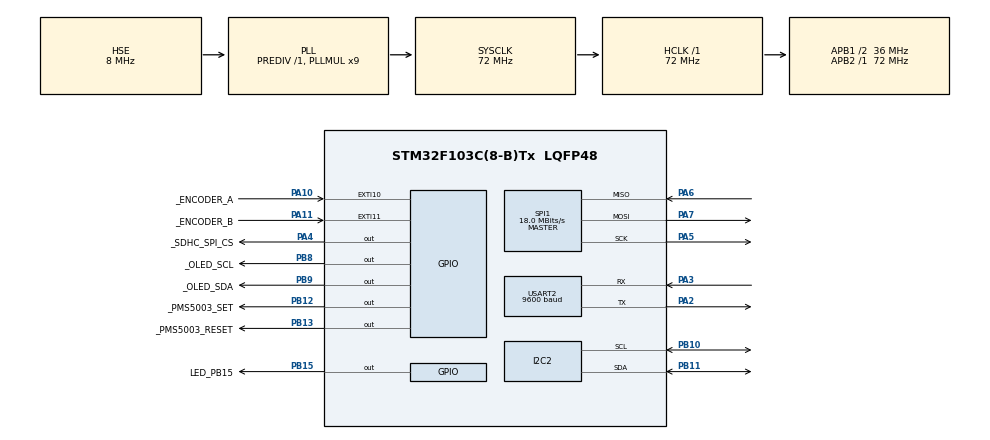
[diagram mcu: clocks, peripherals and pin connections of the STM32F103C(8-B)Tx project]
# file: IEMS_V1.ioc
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Dma.I2C2_RX.0.Direction=DMA_PERIPH_TO_MEMORY
Dma.I2C2_RX.0.Instance=DMA1_Channel5
Dma.I2C2_RX.0.MemDataAlignment=DMA_MDATAALIGN_BYTE
Dma.I2C2_RX.0.MemInc=DMA_MINC_ENABLE
Dma.I2C2_RX.0.Mode=DMA_NORMAL
Dma.I2C2_RX.0.PeriphDataAlignment=DMA_PDATAALIGN_BYTE
Dma.I2C2_RX.0.PeriphInc=DMA_PINC_DISABLE
Dma.I2C2_RX.0.Priority=DMA_PRIORITY_LOW
Dma.I2C2_TX.1.Direction=DMA_MEMORY_TO_PERIPH
Dma.I2C2_TX.1.Instance=DMA1_Channel4
Dma.I2C2_TX.1.MemDataAlignment=DMA_MDATAALIGN_BYTE
Dma.I2C2_TX.1.MemInc=DMA_MINC_ENABLE
Dma.I2C2_TX.1.Mode=DMA_NORMAL
Dma.I2C2_TX.1.PeriphDataAlignment=DMA_PDATAALIGN_BYTE
Dma.I2C2_TX.1.PeriphInc=DMA_PINC_DISABLE
Dma.I2C2_TX.1.Priority=DMA_PRIORITY_LOW
Dma.Request0=I2C2_RX
Dma.Request1=I2C2_TX
Dma.Request2=USART2_RX
Dma.Request3=USART2_TX
Dma.USART2_RX.2.Direction=DMA_PERIPH_TO_MEMORY
Dma.USART2_RX.2.Instance=DMA1_Channel6
Dma.USART2_RX.2.MemDataAlignment=DMA_MDATAALIGN_BYTE
Dma.USART2_RX.2.MemInc=DMA_MINC_ENABLE
Dma.USART2_RX.2.Mode=DMA_NORMAL
Dma.USART2_RX.2.PeriphDataAlignment=DMA_PDATAALIGN_BYTE
Dma.USART2_RX.2.PeriphInc=DMA_PINC_DISABLE
Dma.USART2_RX.2.Priority=DMA_PRIORITY_LOW
Dma.USART2_TX.3.Direction=DMA_MEMORY_TO_PERIPH
Dma.USART2_TX.3.Instance=DMA1_Channel7
Dma.USART2_TX.3.MemDataAlignment=DMA_MDATAALIGN_BYTE
Dma.USART2_TX.3.MemInc=DMA_MINC_ENABLE
Dma.USART2_TX.3.Mode=DMA_NORMAL
Dma.USART2_TX.3.PeriphDataAlignment=DMA_PDATAALIGN_BYTE
Dma.USART2_TX.3.PeriphInc=DMA_PINC_DISABLE
Dma.USART2_TX.3.Priority=DMA_PRIORITY_LOW
I2C2.I2C_Mode=I2C_Standard
Mcu.Family=STM32F1
Mcu.Name=STM32F103C(8-B)Tx
Mcu.Package=LQFP48
NVIC.DMA1_Channel4_IRQn=true\:2\:0\:true\:false\:true\:false\:true\:true
NVIC.DMA1_Channel5_IRQn=true\:2\:1\:true\:false\:true\:false\:true\:true
NVIC.DMA1_Channel6_IRQn=true\:2\:2\:true\:false\:true\:false\:true\:true
NVIC.DMA1_Channel7_IRQn=true\:2\:3\:true\:false\:true\:false\:true\:true
NVIC.EXTI15_10_IRQn=true\:0\:2\:true\:false\:true\:true\:true\:true
NVIC.I2C2_EV_IRQn=true\:3\:0\:true\:false\:true\:true\:true\:true
NVIC.PriorityGroup=NVIC_PRIORITYGROUP_2
NVIC.SPI1_IRQn=true\:0\:3\:true\:false\:true\:true\:true\:true
NVIC.TIM2_IRQn=true\:1\:1\:true\:false\:true\:true\:true\:true
NVIC.TIM3_IRQn=true\:1\:0\:true\:false\:true\:true\:true\:true
NVIC.USART2_IRQn=true\:3\:1\:true\:false\:true\:true\:true\:true
PA10.GPIO_Label=_ENCODER_A
PA10.GPIO_ModeDefaultEXTI=GPIO_MODE_IT_RISING_FALLING
PA10.GPIO_PuPd=GPIO_PULLUP
PA10.Signal=GPXTI10
PA11.GPIO_Label=_ENCODER_B
PA11.GPIO_ModeDefaultEXTI=GPIO_MODE_IT_RISING_FALLING
PA11.GPIO_PuPd=GPIO_PULLUP
PA11.Signal=GPXTI11
PA13.Mode=Serial_Wire
PA13.Signal=SYS_JTMS-SWDIO
PA14.Mode=Serial_Wire
PA14.Signal=SYS_JTCK-SWCLK
PA2.Mode=Asynchronous
PA2.Signal=USART2_TX
PA3.Mode=Asynchronous
PA3.Signal=USART2_RX
PA4.GPIO_Label=_SDHC_SPI_CS
PA4.GPIO_PuPd=GPIO_PULLUP
PA4.GPIO_Speed=GPIO_SPEED_FREQ_HIGH
PA4.PinState=GPIO_PIN_SET
PA4.Signal=GPIO_Output
PA5.Mode=Full_Duplex_Master
PA5.Signal=SPI1_SCK
PA6.Mode=Full_Duplex_Master
PA6.Signal=SPI1_MISO
PA7.Mode=Full_Duplex_Master
PA7.Signal=SPI1_MOSI
PB10.Mode=I2C
PB10.Signal=I2C2_SCL
PB11.Mode=I2C
PB11.Signal=I2C2_SDA
PB12.GPIO_Label=_PMS5003_SET
PB12.GPIO_PuPd=GPIO_PULLUP
PB12.GPIO_Speed=GPIO_SPEED_FREQ_HIGH
PB12.Signal=GPIO_Output
PB13.GPIO_Label=_PMS5003_RESET
PB13.GPIO_PuPd=GPIO_PULLUP
PB13.GPIO_Speed=GPIO_SPEED_FREQ_HIGH
PB13.Signal=GPIO_Output
PB15.GPIO_Label=LED_PB15
PB15.Signal=GPIO_Output
PB8.GPIO_Label=_OLED_SCL
PB8.GPIO_ModeDefaultOutputPP=GPIO_MODE_OUTPUT_OD
PB8.GPIO_PuPd=GPIO_PULLUP
PB8.GPIO_Speed=GPIO_SPEED_FREQ_HIGH
PB8.PinState=GPIO_PIN_SET
PB8.Signal=GPIO_Output
PB9.GPIO_Label=_OLED_SDA
PB9.GPIO_ModeDefaultOutputPP=GPIO_MODE_OUTPUT_OD
PB9.GPIO_PuPd=GPIO_PULLUP
PB9.GPIO_Speed=GPIO_SPEED_FREQ_HIGH
PB9.PinState=GPIO_PIN_SET
PB9.Signal=GPIO_Output
PD0-OSC_IN.Mode=HSE-External-Oscillator
PD0-OSC_IN.Signal=RCC_OSC_IN
PD1-OSC_OUT.Mode=HSE-External-Oscillator
PD1-OSC_OUT.Signal=RCC_OSC_OUT
ProjectManager.HeapSize=0x200
ProjectManager.StackSize=0x400
ProjectManager.TargetToolchain=MDK-ARM V5.32
RCC.AHBFreq_Value=72000000
RCC.APB1CLKDivider=RCC_HCLK_DIV2
RCC.APB1Freq_Value=36000000
RCC.APB1TimFreq_Value=72000000
RCC.APB2Freq_Value=72000000
RCC.APB2TimFreq_Value=72000000
RCC.HCLKFreq_Value=72000000
RCC.PLLMUL=RCC_PLL_MUL9
RCC.PLLSourceVirtual=RCC_PLLSOURCE_HSE
RCC.SYSCLKFreq_VALUE=72000000
RCC.SYSCLKSource=RCC_SYSCLKSOURCE_PLLCLK
RCC.USBFreq_Value=72000000
SPI1.BaudRatePrescaler=SPI_BAUDRATEPRESCALER_4
SPI1.CalculateBaudRate=18.0 MBits/s
SPI1.Direction=SPI_DIRECTION_2LINES
SPI1.Mode=SPI_MODE_MASTER
SPI1.VirtualType=VM_MASTER
TIM2.Period=99
TIM2.Prescaler=7199
TIM3.Period=4999
TIM3.Prescaler=7199
USART2.BaudRate=9600
USART2.VirtualMode=VM_ASYNC
VP_FATFS_VS_Generic.Mode=User_defined
VP_TIM2_VS_ClockSourceINT.Mode=Internal
VP_TIM3_VS_ClockSourceINT.Mode=Internal
board=custom

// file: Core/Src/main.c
/* USER CODE BEGIN Header */
/**
  ******************************************************************************
  * @file           : main.c
  * @brief          : Main program body
  ******************************************************************************
  * @attention
  *
  * Copyright (c) 2025 STMicroelectronics.
  * All rights reserved.
  *
  * This software is licensed under terms that can be found in the LICENSE file
  * in the root directory of this software component.
  * If no LICENSE file comes with this software, it is provided AS-IS.
  *
  ******************************************************************************
  */
/* USER CODE END Header */
#include "main.h"
#include "dma.h"
#include "fatfs.h"
#include "i2c.h"
#include "spi.h"
#include "tim.h"
#include "usart.h"
#include "gpio.h"

/* USER CODE BEGIN Includes */
#include "00_cpp_main.h"

/* USER CODE END Includes */

void SystemClock_Config(void);

int main(void)
{

  /* MCU Configuration--------------------------------------------------------*/

  /* Reset of all peripherals, Initializes the Flash interface and the Systick. */
  HAL_Init();

  /* Configure the system clock */
  SystemClock_Config();

  /* Initialize all configured peripherals */
  MX_GPIO_Init();
  MX_DMA_Init();
  MX_I2C2_Init();
  MX_TIM3_Init();
  MX_TIM2_Init();
  MX_USART2_UART_Init();
  MX_SPI1_Init();
  MX_FATFS_Init();
  /* USER CODE BEGIN 2 */

  cpp_main();

  /* USER CODE END 2 */

  /* Infinite loop */
  while (1)
  {

  }
}

void SystemClock_Config(void)
{
  RCC_OscInitTypeDef RCC_OscInitStruct = {0};
  RCC_ClkInitTypeDef RCC_ClkInitStruct = {0};

  /** Initializes the RCC Oscillators according to the specified parameters
  * in the RCC_OscInitTypeDef structure.
  */
  RCC_OscInitStruct.OscillatorType = RCC_OSCILLATORTYPE_HSE;
  RCC_OscInitStruct.HSEState = RCC_HSE_ON;
  RCC_OscInitStruct.HSEPredivValue = RCC_HSE_PREDIV_DIV1;
  RCC_OscInitStruct.HSIState = RCC_HSI_ON;
  RCC_OscInitStruct.PLL.PLLState = RCC_PLL_ON;
  RCC_OscInitStruct.PLL.PLLSource = RCC_PLLSOURCE_HSE;
  RCC_OscInitStruct.PLL.PLLMUL = RCC_PLL_MUL9;
  if (HAL_RCC_OscConfig(&RCC_OscInitStruct) != HAL_OK)
  {
    Error_Handler();
  }

  /** Initializes the CPU, AHB and APB buses clocks
  */
  RCC_ClkInitStruct.ClockType = RCC_CLOCKTYPE_HCLK|RCC_CLOCKTYPE_SYSCLK
                              |RCC_CLOCKTYPE_PCLK1|RCC_CLOCKTYPE_PCLK2;
  RCC_ClkInitStruct.SYSCLKSource = RCC_SYSCLKSOURCE_PLLCLK;
  RCC_ClkInitStruct.AHBCLKDivider = RCC_SYSCLK_DIV1;
  RCC_ClkInitStruct.APB1CLKDivider = RCC_HCLK_DIV2;
  RCC_ClkInitStruct.APB2CLKDivider = RCC_HCLK_DIV1;

  if (HAL_RCC_ClockConfig(&RCC_ClkInitStruct, FLASH_LATENCY_2) != HAL_OK)
  {
    Error_Handler();
  }
}

void Error_Handler(void)
{
  __disable_irq();
  while (1)
  {
  }
}
